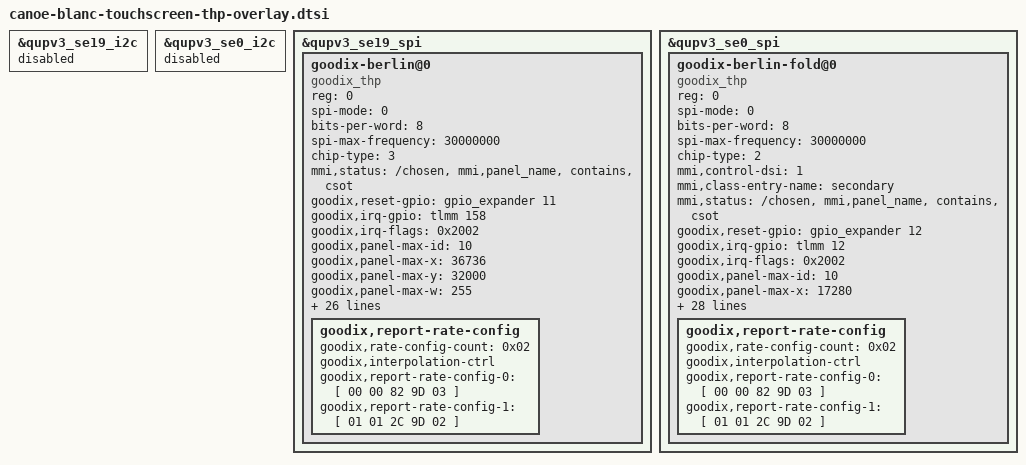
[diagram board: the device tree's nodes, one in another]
/*
 * Copyright (c) 2022, The Linux Foundation. All rights reserved.
 *
 * This program is free software; you can redistribute it and/or modify
 * it under the terms of the GNU General Public License version 2 and
 * only version 2 as published by the Free Software Foundation.
 *
 * This program is distributed in the hope that it will be useful,
 * but WITHOUT ANY WARRANTY; without even the implied warranty of
 * MERCHANTABILITY or FITNESS FOR A PARTICULAR PURPOSE.  See the
 * GNU General Public License for more details.
 */
#include <dt-bindings/gpio/gpio.h>
//#include <dt-bindings/iio/qcom,spmi-adc5-gen4-pmk8850.h>

&qupv3_se19_i2c {
	status = "disabled";
};
&qupv3_se0_i2c {
	status = "disabled";
};
/*
&pmk8850_gpios {
	stylus_clk_ctrl {
		stylus_clk_active: stylus_clk_active {
			pins = "gpio5";
			function = "func2";
			bias-disable; // No Pull
			output-enable; // digital output, no invert
			intput-disable; // prevent GPIO from being set to DIO
			power-source = <0>;
		};
		stylus_clk_suspend: stylus_clk_suspend {
			pins = "gpio5";
			function = "func2";
			bias-high-impedance;
			output-enable; // digital output, no invert
			intput-disable; // prevent GPIO from being set to DIO
			power-source = <0>;
		};
	};
};
*/

&qupv3_se19_spi {
	#address-cells = <1>;
	#size-cells = <0>;

	status = "ok";

	goodix-berlin@0 {
		status = "ok";
		compatible = "goodix_thp";
		reg = <0>;

		spi-mode = <0>;
		bits-per-word = <8>;
		spi-max-frequency = <30000000>;
		chip-type = <3>; // 1: 9897 2: 9916 3: 9966

		mmi,status = "/chosen","mmi,panel_name","contains","csot";
		goodix,reset-gpio = <&gpio_expander 11 0>;
		goodix,irq-gpio = <&tlmm 158 0x2002>;
		goodix,irq-flags = <0x2002>; /* 1:trigger rising, 2:trigger falling;*/
		goodix,panel-max-id = <10>;
		goodix,panel-max-x = <36736>; /* 2296*16 */
		goodix,panel-max-y = <32000>; /* 2000*16 */
		goodix,panel-max-w = <255>;
		goodix,panel-max-p = <4096>;
		goodix,avdd-gpio = <&gpio_expander 4 0>;
		goodix,iovdd-gpio = <&gpio_expander 3 0>;

		goodix,panel-key-map = <158 172 217>; /*BACK,HOMEPAGE,SEARCH*/
		goodix,power-on-delay-us = <100000>; /*300ms*/
		goodix,power-off-delay-us = <10000>;

		pinctrl-names = "pmx_ts_active", "pmx_ts_suspend", "pmx_ts_release",  "stylus_clk_active", "stylus_clk_suspend";
		pinctrl-0 = <&ts_active>;
		pinctrl-1 = <&ts_int_suspend &ts_reset_suspend>;
		pinctrl-2 = <&ts_release>;
//		pinctrl-3 = <&stylus_clk_active>;
//		pinctrl-4 = <&stylus_clk_suspend>;
		goodix,firmware-name = "goodix_firmware.bin";
		goodix,config-name = "goodix_cfg_group.bin";
		goodix,gpio-expander;
		goodix,edge-ctrl;
		goodix,interpolation-ctrl;
		goodix,gesture-wait-pm;
		goodix,sample-ctrl;
		goodix,stowed-mode-ctrl;
		goodix,pocket-mode-ctrl;
		mmi,power-off-suspend;
		mmi,enable-gestures;
		mmi,usb-charger-detection;
		mmi,supported_gesture_type = <0x07>;
		mmi,resolution_boost = <16>;
		goodix,stylus_mode-ctrl;

		goodix,sched-priority = <90>;
		goodix,cpu-affinity = <0xf0>;
#if 0
		/* report rate config example, with fps info*/
		goodix,report-rate-config {
			goodix,rate-config-count = /bits/ 8 <0x03>;
			goodix,refresh-rate-ctrl;
			goodix,interpolation-ctrl;

			/* config item 0 */
			goodix,report-rate-config-0 = [
				00	   /* interpolation_flag */
				00 01  /* refresh_rate[0] (1Hz) */
				00 78  /* refresh_rate[1] (120Hz) */
				00 82  /* report_rate (130Hz) */
				9D 03  /* command */
			];

			/* config item 1 */
			goodix,report-rate-config-1 = [
				00
				00 90  // 144Hz
				00 A5  // 165Hz
				00 DC  // 220Hz
				9D 01
			];

			/* config item 2 */
			goodix,report-rate-config-2 = [
				01
				00 01  // 1Hz
				00 A5  // 165Hz
				01 2C  // 300Hz
				9D 02
			];
		};
#endif
		/* report rate config example, without fps info */
		goodix,report-rate-config {
			goodix,rate-config-count = /bits/ 8 <0x02>;
			goodix,interpolation-ctrl;

			/* config item 0 */
			goodix,report-rate-config-0 = [
				00
				00 82 //130HZ
				9D 03
			];

			/* config item 1 */
			goodix,report-rate-config-1 = [
				01
				01 2C //300Hz
				9D 02
			];
		};
	};
};

#if 1
&qupv3_se0_spi {
	#address-cells = <1>;
	#size-cells = <0>;

	status = "ok";

	goodix-berlin-fold@0 {
		status = "ok";
		compatible = "goodix_thp";
		reg = <0>;

		spi-mode = <0>;
		bits-per-word = <8>;
		spi-max-frequency = <30000000>;
		chip-type = <2>; // 1: 9897 2: 9916 3: 9966
		mmi,control-dsi = <1>;
		mmi,class-entry-name = "secondary";

		mmi,status = "/chosen","mmi,panel_name","contains","csot";
		goodix,reset-gpio = <&gpio_expander 12 0>;
		goodix,irq-gpio = <&tlmm 12 0x2002>;
		goodix,irq-flags = <0x2002>; /* 1:trigger rising, 2:trigger falling;*/
		goodix,panel-max-id = <10>;
		goodix,panel-max-x = <17280>; /* 1080*16 */
		goodix,panel-max-y = <42240>; /* 2640*16 */
		goodix,panel-max-w = <255>;
		goodix,panel-max-p = <4096>;
		goodix,avdd-gpio = <&gpio_expander 8 0>;
		goodix,iovdd-gpio = <&gpio_expander 9 0>;

		goodix,panel-key-map = <158 172 217>; /*BACK,HOMEPAGE,SEARCH*/
		goodix,power-on-delay-us = <100000>; /*300ms*/
		goodix,power-off-delay-us = <10000>;

		pinctrl-names = "pmx_ts_active", "pmx_ts_suspend", "pmx_ts_release",  "stylus_clk_active", "stylus_clk_suspend";
		pinctrl-0 = <&ts_active>;
		pinctrl-1 = <&ts_int_suspend &ts_reset_suspend>;
		pinctrl-2 = <&ts_release>;
//		pinctrl-3 = <&stylus_clk_active>;
//		pinctrl-4 = <&stylus_clk_suspend>;
		goodix,firmware-name = "goodix_firmware.bin";
		goodix,config-name = "goodix_cfg_group.bin";
		goodix,gpio-expander;
		goodix,edge-ctrl;
		goodix,interpolation-ctrl;
		goodix,gesture-wait-pm;
		goodix,sample-ctrl;
		goodix,stowed-mode-ctrl;
		goodix,pocket-mode-ctrl;
		mmi,power-off-suspend;
		mmi,enable-gestures;
		mmi,usb-charger-detection;
		mmi,supported_gesture_type = <0x07>;
		mmi,resolution_boost = <16>;
		goodix,stylus_mode-ctrl;

		goodix,sched-priority = <90>;
		goodix,cpu-affinity = <0xf0>;
#if 0
		/* report rate config example, with fps info*/
		goodix,report-rate-config {
			goodix,rate-config-count = /bits/ 8 <0x03>;
			goodix,refresh-rate-ctrl;
			goodix,interpolation-ctrl;

			/* config item 0 */
			goodix,report-rate-config-0 = [
				00	   /* interpolation_flag */
				00 01  /* refresh_rate[0] (1Hz) */
				00 78  /* refresh_rate[1] (120Hz) */
				00 82  /* report_rate (130Hz) */
				9D 03  /* command */
			];

			/* config item 1 */
			goodix,report-rate-config-1 = [
				00
				00 90  // 144Hz
				00 A5  // 165Hz
				00 DC  // 220Hz
				9D 01
			];

			/* config item 2 */
			goodix,report-rate-config-2 = [
				01
				00 01  // 1Hz
				00 A5  // 165Hz
				01 2C  // 300Hz
				9D 02
			];
		};
#endif
		/* report rate config example, without fps info */
		goodix,report-rate-config {
			goodix,rate-config-count = /bits/ 8 <0x02>;
			goodix,interpolation-ctrl;

			/* config item 0 */
			goodix,report-rate-config-0 = [
				00
				00 82 //130HZ
				9D 03
			];

			/* config item 1 */
			goodix,report-rate-config-1 = [
				01
				01 2C //300Hz
				9D 02
			];
		};
	};
};
#endif
